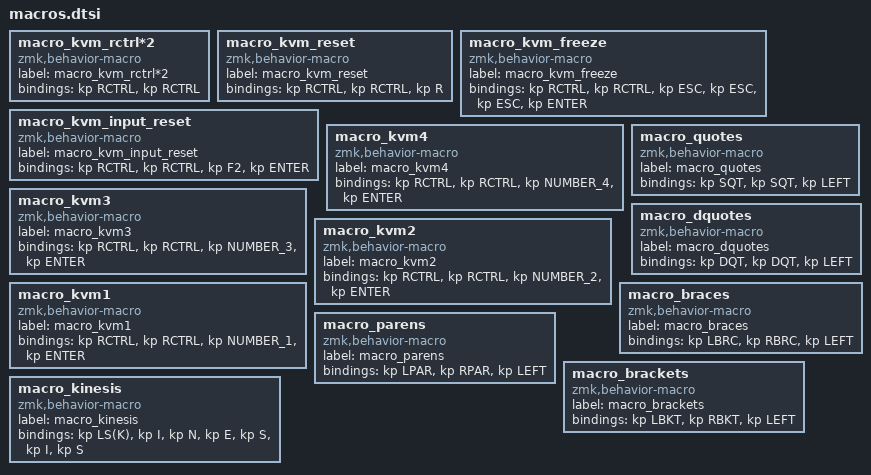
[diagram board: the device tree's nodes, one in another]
macro_kvm_rctrl*2: macro_kvm_rctrl*2{
compatible = "zmk,behavior-macro";
label = "macro_kvm_rctrl*2";
#binding-cells = <0>;
bindings = <&kp RCTRL>, <&kp RCTRL>;
};
macro_kvm_reset: macro_kvm_reset{
compatible = "zmk,behavior-macro";
label = "macro_kvm_reset";
#binding-cells = <0>;
bindings = <&kp RCTRL>, <&kp RCTRL>, <&kp R>;
};
macro_kvm_freeze: macro_kvm_freeze{
compatible = "zmk,behavior-macro";
label = "macro_kvm_freeze";
#binding-cells = <0>;
bindings = <&kp RCTRL>, <&kp RCTRL>, <&kp ESC>, <&kp ESC>, <&kp ESC>, <&kp ENTER>;
};
macro_kvm_input_reset: macro_kvm_input_reset{
compatible = "zmk,behavior-macro";
label = "macro_kvm_input_reset";
#binding-cells = <0>;
bindings = <&kp RCTRL>, <&kp RCTRL>, <&kp F2>, <&kp ENTER>;
};
macro_kvm4: macro_kvm4{
compatible = "zmk,behavior-macro";
label = "macro_kvm4";
#binding-cells = <0>;
bindings = <&kp RCTRL>, <&kp RCTRL>, <&kp NUMBER_4>, <&kp ENTER>;
};
macro_kvm3: macro_kvm3{
compatible = "zmk,behavior-macro";
label = "macro_kvm3";
#binding-cells = <0>;
bindings = <&kp RCTRL>, <&kp RCTRL>, <&kp NUMBER_3>, <&kp ENTER>;
};
macro_kvm2: macro_kvm2{
compatible = "zmk,behavior-macro";
label = "macro_kvm2";
#binding-cells = <0>;
bindings = <&kp RCTRL>, <&kp RCTRL>, <&kp NUMBER_2>, <&kp ENTER>;
};
macro_kvm1: macro_kvm1{
compatible = "zmk,behavior-macro";
label = "macro_kvm1";
#binding-cells = <0>;
bindings = <&kp RCTRL>, <&kp RCTRL>, <&kp NUMBER_1>, <&kp ENTER>;
};
macro_quotes: macro_quotes{
compatible = "zmk,behavior-macro";
label = "macro_quotes";
#binding-cells = <0>;
bindings = <&kp SQT>, <&kp SQT>, <&kp LEFT>;
};
macro_dquotes: macro_dquotes{
compatible = "zmk,behavior-macro";
label = "macro_dquotes";
#binding-cells = <0>;
bindings = <&kp DQT>, <&kp DQT>, <&kp LEFT>;
};
macro_braces: macro_braces{
compatible = "zmk,behavior-macro";
label = "macro_braces";
#binding-cells = <0>;
bindings = <&kp LBRC>, <&kp RBRC>, <&kp LEFT>;
};
macro_parens: macro_parens{
compatible = "zmk,behavior-macro";
label = "macro_parens";
#binding-cells = <0>;
bindings = <&kp LPAR>, <&kp RPAR>, <&kp LEFT>;
};
macro_brackets: macro_brackets{
compatible = "zmk,behavior-macro";
label = "macro_brackets";
#binding-cells = <0>;
bindings = <&kp LBKT>, <&kp RBKT>, <&kp LEFT>;
};
macro_kinesis: macro_kinesis{
compatible = "zmk,behavior-macro";
label = "macro_kinesis";
#binding-cells = <0>;
bindings = <&kp LS(K)>, <&kp I>, <&kp N>, <&kp E>, <&kp S>, <&kp I>, <&kp S>;
};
